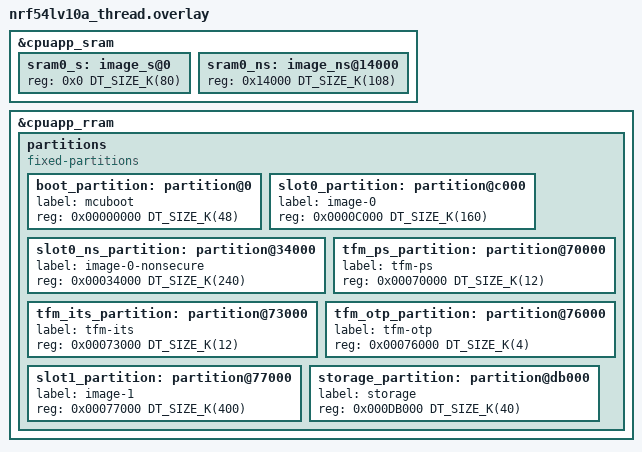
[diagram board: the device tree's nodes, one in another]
/*
 * Copyright (c) 2026 Nordic Semiconductor ASA
 *
 * SPDX-License-Identifier: LicenseRef-Nordic-5-Clause
 */

/*
 * Thread (OpenThread)-optimized TF-M partition layout for nRF54LV10A
 *
 * nRF54LV10A has 1012 kB of RRAM and 192 kB of SRAM.
 * TrustZone flash region alignment: 4 kB (MPC-based)
 * TrustZone RAM region alignment:   4 kB
 * RRAM erase-block-size:            4 kB
 *
 * Optimized for Thread (802.15.4) applications with:
 * - Medium TF-M for Thread commissioning crypto
 * - MCUboot for Thread OTA
 * - ITS for Thread operational dataset
 * - Larger NS partition for OpenThread stack
 *
 * Suitable for: Thread sensors, Thread end devices on nRF54LV10A
 */

&cpuapp_sram {
	sram0_s: image_s@0 {
		#address-cells = <1>;
		#size-cells = <1>;
		reg = <0x0 DT_SIZE_K(80)>;
		ranges = <0x0 0x0 DT_SIZE_K(80)>;
	};

	/* 108 kB NS — 4 kB unused at top */
	sram0_ns: image_ns@14000 {
		#address-cells = <1>;
		#size-cells = <1>;
		reg = <0x14000 DT_SIZE_K(108)>;
		ranges = <0x0 0x14000 DT_SIZE_K(108)>;
	};
};

&cpuapp_rram {
	partitions {
		compatible = "fixed-partitions";
		#address-cells = <1>;
		#size-cells = <1>;

		/*
		 * Flash layout (all addresses 4 kB aligned):
		 *
		 * 0x00000000  MCUboot bootloader        (48 kB)
		 * 0x0000C000  Primary slot:
		 *   0x0000C000  TF-M secure image       (160 kB)
		 *   0x00034000  Non-secure Thread app    (240 kB)
		 * 0x00070000  TF-M PS                    (12 kB)
		 * 0x00073000  TF-M ITS                   (12 kB)
		 * 0x00076000  TF-M OTP / NV counters      (4 kB)
		 * 0x00077000  Secondary slot            (400 kB)
		 * 0x000DB000  Non-secure storage (NVS)    (40 kB)
		 *
		 * Primary = 160 + 240 = 400 kB = Secondary
		 * Total: 48 + 400 + 12 + 12 + 4 + 400 + 40 = 916 kB
		 */

		boot_partition: partition@0 {
			label = "mcuboot";
			reg = <0x00000000 DT_SIZE_K(48)>;
		};

		slot0_partition: partition@c000 {
			label = "image-0";
			reg = <0x0000C000 DT_SIZE_K(160)>;
		};

		slot0_ns_partition: partition@34000 {
			label = "image-0-nonsecure";
			reg = <0x00034000 DT_SIZE_K(240)>;
		};

		tfm_ps_partition: partition@70000 {
			label = "tfm-ps";
			reg = <0x00070000 DT_SIZE_K(12)>;
		};

		tfm_its_partition: partition@73000 {
			label = "tfm-its";
			reg = <0x00073000 DT_SIZE_K(12)>;
		};

		tfm_otp_partition: partition@76000 {
			label = "tfm-otp";
			reg = <0x00076000 DT_SIZE_K(4)>;
		};

		slot1_partition: partition@77000 {
			label = "image-1";
			reg = <0x00077000 DT_SIZE_K(400)>;
		};

		storage_partition: partition@db000 {
			label = "storage";
			reg = <0x000DB000 DT_SIZE_K(40)>;
		};
	};
};
